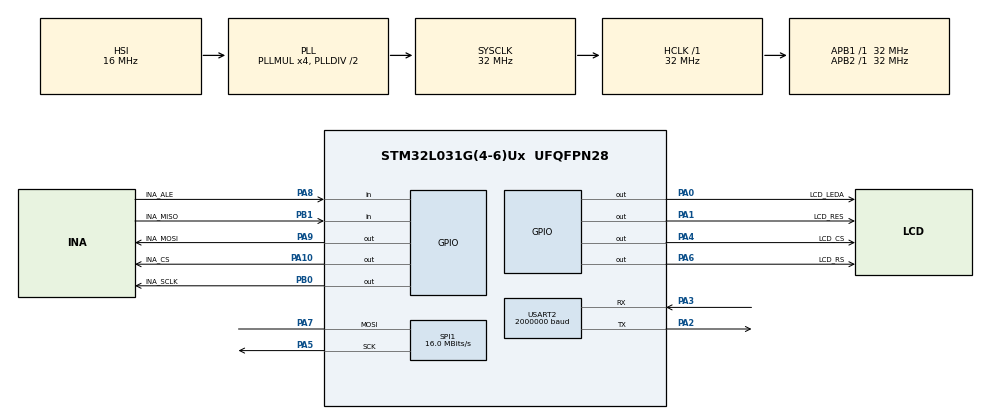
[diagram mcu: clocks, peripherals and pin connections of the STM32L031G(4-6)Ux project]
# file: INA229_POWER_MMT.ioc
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Dma.Request0=USART2_RX
Dma.Request1=USART2_TX
Dma.USART2_RX.0.Direction=DMA_PERIPH_TO_MEMORY
Dma.USART2_RX.0.Instance=DMA1_Channel5
Dma.USART2_RX.0.MemDataAlignment=DMA_MDATAALIGN_BYTE
Dma.USART2_RX.0.MemInc=DMA_MINC_ENABLE
Dma.USART2_RX.0.Mode=DMA_NORMAL
Dma.USART2_RX.0.PeriphDataAlignment=DMA_PDATAALIGN_BYTE
Dma.USART2_RX.0.PeriphInc=DMA_PINC_DISABLE
Dma.USART2_RX.0.Priority=DMA_PRIORITY_LOW
Dma.USART2_TX.1.Direction=DMA_MEMORY_TO_PERIPH
Dma.USART2_TX.1.Instance=DMA1_Channel4
Dma.USART2_TX.1.MemDataAlignment=DMA_MDATAALIGN_BYTE
Dma.USART2_TX.1.MemInc=DMA_MINC_ENABLE
Dma.USART2_TX.1.Mode=DMA_NORMAL
Dma.USART2_TX.1.PeriphDataAlignment=DMA_PDATAALIGN_BYTE
Dma.USART2_TX.1.PeriphInc=DMA_PINC_DISABLE
Dma.USART2_TX.1.Priority=DMA_PRIORITY_LOW
Mcu.Family=STM32L0
Mcu.Name=STM32L031G(4-6)Ux
Mcu.Package=UFQFPN28
NVIC.DMA1_Channel4_5_6_7_IRQn=true\:0\:0\:false\:false\:true\:false\:true\:true
NVIC.TIM2_IRQn=true\:0\:0\:false\:false\:true\:true\:true\:true
NVIC.USART2_IRQn=true\:0\:0\:false\:false\:true\:true\:true\:true
PA0-CK_IN.GPIO_Label=LCD_LEDA
PA0-CK_IN.GPIO_Speed=GPIO_SPEED_FREQ_VERY_HIGH
PA0-CK_IN.Signal=GPIO_Output
PA1.GPIO_Label=LCD_RES
PA1.GPIO_Speed=GPIO_SPEED_FREQ_VERY_HIGH
PA1.Signal=GPIO_Output
PA10.GPIO_Label=INA_CS
PA10.GPIO_Speed=GPIO_SPEED_FREQ_VERY_HIGH
PA10.PinState=GPIO_PIN_SET
PA10.Signal=GPIO_Output
PA13.Mode=Serial_Wire
PA13.Signal=SYS_SWDIO
PA14.Mode=Serial_Wire
PA14.Signal=SYS_SWCLK
PA2.Mode=Asynchronous
PA2.Signal=USART2_TX
PA3.Mode=Asynchronous
PA3.Signal=USART2_RX
PA4.GPIO_Label=LCD_CS
PA4.GPIO_Speed=GPIO_SPEED_FREQ_VERY_HIGH
PA4.PinState=GPIO_PIN_SET
PA4.Signal=GPIO_Output
PA5.Mode=Simplex_Bidirectional_Master
PA5.Signal=SPI1_SCK
PA6.GPIO_Label=LCD_RS
PA6.GPIO_Speed=GPIO_SPEED_FREQ_VERY_HIGH
PA6.Signal=GPIO_Output
PA7.Mode=Simplex_Bidirectional_Master
PA7.Signal=SPI1_MOSI
PA8.GPIO_Label=INA_ALE
PA8.Signal=GPIO_Input
PA9.GPIO_Label=INA_MOSI
PA9.GPIO_Speed=GPIO_SPEED_FREQ_VERY_HIGH
PA9.Signal=GPIO_Output
PB0.GPIO_Label=INA_SCLK
PB0.GPIO_Speed=GPIO_SPEED_FREQ_VERY_HIGH
PB0.Signal=GPIO_Output
PB1.GPIO_Label=INA_MISO
PB1.Signal=GPIO_Input
ProjectManager.HeapSize=0x100
ProjectManager.StackSize=0x400
ProjectManager.TargetToolchain=MDK-ARM V5.32
RCC.AHBFreq_Value=32000000
RCC.APB1Freq_Value=32000000
RCC.APB1TimFreq_Value=32000000
RCC.APB2Freq_Value=32000000
RCC.APB2TimFreq_Value=32000000
RCC.HCLKFreq_Value=32000000
RCC.HSE_VALUE=8000000
RCC.HSI16_VALUE=16000000
RCC.HSI_VALUE=16000000
RCC.LSE_VALUE=32768
RCC.MSI_VALUE=2097000
RCC.PLLMUL=RCC_PLLMUL_4
RCC.SYSCLKFreq_VALUE=32000000
RCC.SYSCLKSource=RCC_SYSCLKSOURCE_PLLCLK
RCC.VCOOutputFreq_Value=64000000
SPI1.CalculateBaudRate=16.0 MBits/s
SPI1.DataSize=SPI_DATASIZE_8BIT
SPI1.Direction=SPI_DIRECTION_1LINE
SPI1.Mode=SPI_MODE_MASTER
SPI1.VirtualType=VM_MASTER
TIM2.AutoReloadPreload=TIM_AUTORELOAD_PRELOAD_ENABLE
TIM2.Period=99
TIM2.Prescaler=31
USART2.BaudRate=2000000
USART2.VirtualMode-Asynchronous=VM_ASYNC
VP_TIM2_VS_ClockSourceINT.Mode=Internal
board=custom

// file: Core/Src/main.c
/* USER CODE BEGIN Header */
/**
  ******************************************************************************
  * @file           : main.c
  * @brief          : Main program body
  ******************************************************************************
  * @attention
  *
  * Copyright (c) 2026 STMicroelectronics.
  * All rights reserved.
  *
  * This software is licensed under terms that can be found in the LICENSE file
  * in the root directory of this software component.
  * If no LICENSE file comes with this software, it is provided AS-IS.
  *
  ******************************************************************************
  */
/* USER CODE END Header */
#include "main.h"
#include "dma.h"
#include "spi.h"
#include "tim.h"
#include "usart.h"
#include "gpio.h"

/* USER CODE BEGIN Includes */
#include "system.h"
/* USER CODE END Includes */

void SystemClock_Config(void);

int main(void)
{

  /* MCU Configuration--------------------------------------------------------*/

  /* Reset of all peripherals, Initializes the Flash interface and the Systick. */
  HAL_Init();

  /* Configure the system clock */
  SystemClock_Config();

  /* Initialize all configured peripherals */
  MX_GPIO_Init();
  MX_DMA_Init();
  MX_USART2_UART_Init();
  MX_SPI1_Init();
  MX_TIM2_Init();
  /* USER CODE BEGIN 2 */
	Global_Init();
  /* USER CODE END 2 */

  /* Infinite loop */
  /* USER CODE BEGIN WHILE */
  while (1)
  {
    UART_Protocol_Process();

    if (g_LcdTaskEnable)
        Lcd_Task();

    INA229_Task();
//		HAL_Delay(100);
//		printf("%d\r\n",number_count);
    /* USER CODE END WHILE */

  }
}

void SystemClock_Config(void)
{
  RCC_OscInitTypeDef RCC_OscInitStruct = {0};
  RCC_ClkInitTypeDef RCC_ClkInitStruct = {0};
  RCC_PeriphCLKInitTypeDef PeriphClkInit = {0};

  /** Configure the main internal regulator output voltage
  */
  __HAL_PWR_VOLTAGESCALING_CONFIG(PWR_REGULATOR_VOLTAGE_SCALE1);

  /** Initializes the RCC Oscillators according to the specified parameters
  * in the RCC_OscInitTypeDef structure.
  */
  RCC_OscInitStruct.OscillatorType = RCC_OSCILLATORTYPE_HSI;
  RCC_OscInitStruct.HSIState = RCC_HSI_ON;
  RCC_OscInitStruct.HSICalibrationValue = RCC_HSICALIBRATION_DEFAULT;
  RCC_OscInitStruct.PLL.PLLState = RCC_PLL_ON;
  RCC_OscInitStruct.PLL.PLLSource = RCC_PLLSOURCE_HSI;
  RCC_OscInitStruct.PLL.PLLMUL = RCC_PLLMUL_4;
  RCC_OscInitStruct.PLL.PLLDIV = RCC_PLLDIV_2;
  if (HAL_RCC_OscConfig(&RCC_OscInitStruct) != HAL_OK)
  {
    Error_Handler();
  }

  /** Initializes the CPU, AHB and APB buses clocks
  */
  RCC_ClkInitStruct.ClockType = RCC_CLOCKTYPE_HCLK|RCC_CLOCKTYPE_SYSCLK
                              |RCC_CLOCKTYPE_PCLK1|RCC_CLOCKTYPE_PCLK2;
  RCC_ClkInitStruct.SYSCLKSource = RCC_SYSCLKSOURCE_PLLCLK;
  RCC_ClkInitStruct.AHBCLKDivider = RCC_SYSCLK_DIV1;
  RCC_ClkInitStruct.APB1CLKDivider = RCC_HCLK_DIV1;
  RCC_ClkInitStruct.APB2CLKDivider = RCC_HCLK_DIV1;

  if (HAL_RCC_ClockConfig(&RCC_ClkInitStruct, FLASH_LATENCY_1) != HAL_OK)
  {
    Error_Handler();
  }
  PeriphClkInit.PeriphClockSelection = RCC_PERIPHCLK_USART2;
  PeriphClkInit.Usart2ClockSelection = RCC_USART2CLKSOURCE_PCLK1;
  if (HAL_RCCEx_PeriphCLKConfig(&PeriphClkInit) != HAL_OK)
  {
    Error_Handler();
  }
}

void Error_Handler(void)
{
  __disable_irq();
  while (1)
  {
  }
}
